# Musca_S1 register map
Vendor: ARM Ltd.; Series: ARMv8-M Mainline; File version: 1.0
CPU: CM33 r0p1, little endian, MPU, no FPU, 3 interrupt priority bits, 8 SAU regions
Registers are 32-bit, read-write, reset 0x0 unless marked. A register's access mark holds for its fields unless they carry their own. Offsets are from the block's base; [hi:lo] are bit positions.

## SPI0
Base 0x40103000
Same registers: SPI0_Secure 0x50103000
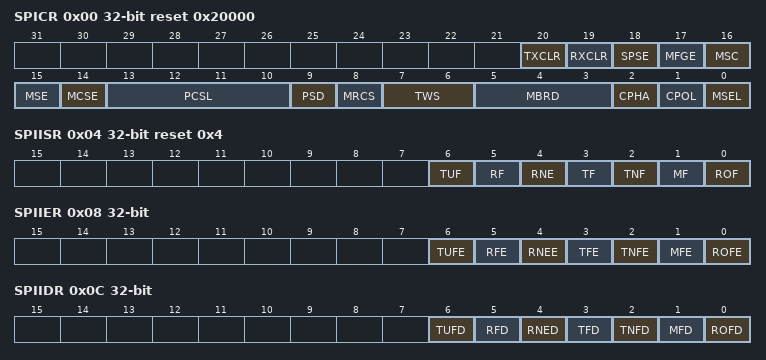
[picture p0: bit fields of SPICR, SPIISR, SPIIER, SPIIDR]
0x00 SPICR reset 0x20000 — Configuration Register
  [20] TXCLR — TX FIFO Clear: Writing a 1 to this bit will clear the TX FIFO. Writing a '0' will have no effect. It returns 0 when read
  [19] RXCLR — RX FIFO Clear: Writing a 1 to this bit will clear the RX FIFO. Writing a 0 will have no effect. It returns '0' when read
  [18] SPSE — Sample Point Shift Enable: When this bit is set and controller is in MASTER receiver mode then sample point of receiving data is shifted with respect to sample point of SPI protocol specification
  [17] MFGE — Mode Fail Generation Enable: When this bit is set the logic generating Mode Fail is enabled
  [16] MSC — Manual Start Command: When manual start mode is enabled (see Manual Start Enable bit of Configuration Register) and TX FIFO is not empty, writing a 1 to this bit will start transmission. Writing a 0 will have no effect. It returns '0' when read
  [15] MSE — Manual Start Enable: When this bit is set do not allow transmission to start until Manual Start Command (see MSC) bit is written with a '1'
  [14] MCSE — Manual Chip Select Enable: When this bit is set, the n_ss_out[3:0] lines will be driven permanently by the encoded peripheral select value regardless of the current state of the main SPI state machine
  [13:10] PCSL — Peripheral Chip Select Lines (master mode only): When Peripheral Select Decode is set then PCSL[3:0] directly drives n_ss_out [3:0], else (PSD is written with 0) PCSL[3:0] drives n_ss_out [3:0]
  [9] PSD — Peripheral Select Decode: When this bit is set allow external 4-to-16 decode (n_ss_out [3:0 = PCSL [3:0]). When Peripheral Select Decode is not set, only 1 of 4 selects n_ss_out[3:0] are active (see PCSL)
  [8] MRCS — Reference Clock Select: When this bit is set the ext_clk is used, otherwise SPI REFERENCE CLOCK is used
  [7:6] TWS — Transfer Word Size: Define size of word to be transferred. This MUST be equal to the FIFO width (FF_W), or a sub-multiple of FF_W to allow multiple word transfers per FIFO word
  [5:3] MBRD — Master Baud Rate Divisor (2 to 256). The SCLK is generated base on SPI REFERENCE CLOCK or ext_clk divided by MBRD
  [2] CPHA — Clock Phase: Selects whether the SPI clock is in active or inactive phase outside the SPI word
  [1] CPOL — External Clock Edge: Selects the SPI clock polarity outside SPI word
  [0] MSEL — Mode Select: Selects SPI controller mode (MASTER/SLAVE)
0x04 SPIISR ro reset 0x4 — Interrupt Status Register
  [6] TUF — TX FIFO Underflow: This bit is reset only by a system reset and cleared only when the register is read
  [5] RF — RX FIFO Full (current FIFO status)
  [4] RNE — RX FIFO Not Empty (current FIFO status)
  [3] TF — TX FIFO Full (current FIFO status)
  [2] TNF — TX FIFO Not Full (current FIFO status)
  [1] MF — Mode Fail: Indicates the voltage on pin n_ss_in is inconsistent with the SPI mode
  [0] ROF — RX FIFO Overflow: This bit is set if an attempt is made to push the RX FIFO when it is full
0x08 SPIIER wo — Interrupt Enable Register
  [6] TUFE — TX FIFO Underflow Enable
  [5] RFE — RX FIFO Full Enable
  [4] RNEE — RX FIFO Not Empty Enable
  [3] TFE — TX FIFO Full Enable
  [2] TNFE — TX FIFO Not Full Enable
  [1] MFE — Mode Fail Enable
  [0] ROFE — RX FIFO Overflow Enable
0x0C SPIIDR wo — Interrupt Disable Register
  [6] TUFD — TX FIFO Underflow Disable
  [5] RFD — RX FIFO Full Disable
  [4] RNED — RX FIFO Not Empty Disable
  [3] TFD — TX FIFO Full Disable
  [2] TNFD — TX FIFO Not Full Disable
  [1] MFD — Mode Fail Disable
  [0] ROFD — RX FIFO Overflow Disable
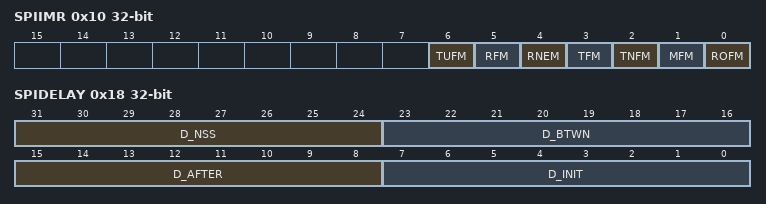
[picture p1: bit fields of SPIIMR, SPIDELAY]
0x10 SPIIMR ro — Interrupt Mask Register
  [6] TUFM — TX FIFO Underflow Mask
  [5] RFM — RX FIFO Full Mask
  [4] RNEM — RX FIFO Not Empty Mask
  [3] TFM — TX FIFO Full Mask
  [2] TNFM — TX FIFO Not Full Mask
  [1] MFM — Mode Fail Mask
  [0] ROFM — RX FIFO Overflow Mask
0x14 SPIENR — SPI Enable Register
  [0] SPIE — SPI Enable: When this bit is set the SPI controller is enabled, otherwise SPI is disabled. When SPI controller is disabled all output enables are inactive and all pins are set to input mode. Writing '0' disables the SPI controller once current transfer of the data word (FF_W) is complete
0x18 SPIDELAY — Delay Register
  [31:24] D_NSS — Delay NSS
  [23:16] D_BTWN — Delay Between
  [15:8] D_AFTER — Delay After
  [7:0] D_INIT — Delay Init
0x1C SPITDR wo — Transmit Data Register
  [7:0] TDATA — Transmit Data: Writes to the TX FIFO location indicated by its internal write address and increments the write address by pushing it
0x20 SPIRDR ro — Receive Data Register
  [7:0] RDATA — Receive Data: Reads the RX FIFO location indicated by the current read address and then increments the read address
0x24 SPISIC — Slave Idle Count Register
  [7:0] SICNT — Slave Idle Count: SPI in slave mode detects a start only when the external SPI master serial clock (sclk_in) is stable (quiescent state) for SPI REFERENCE CLOCK cycles specified by slave idle count register or when the SPI is deselected.
0x28 SPITTH — TX FIFO Threshold Register
  [2:0] TTRSH — TX Threshold: Defines the level at which the TX FIFO not full interrupt is generated.
0x2C SPIRTH — RX FIFO Threshold Register
  [2:0] RTRSH — RX Threshold: Defines the level at which the RX FIFO not empty interrupt is generated.
